# R7FA6M1AD register map
Vendor: Renesas; Series: RA6; File version: 1.2
CPU: CM4 r0p1, little endian, MPU, FPU, VTOR, 4 interrupt priority bits
Registers are 8-bit, read-write, reset 0x0 unless marked. A register's access mark holds for its fields unless they carry their own. Offsets are from the block's base; [hi:lo] are bit positions.

## CTSU — Capacitive Touch Sensing Unit
Base 0x40081000
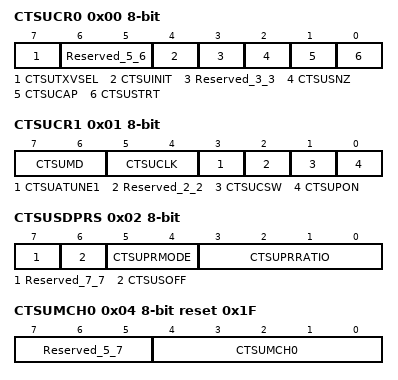
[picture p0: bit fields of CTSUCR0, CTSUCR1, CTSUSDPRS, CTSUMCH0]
0x00 CTSUCR0 — CTSU Control Register 0
  [7] CTSUTXVSEL — CTSU Transmission power supply selection
  [6:5] Reserved_5_6 — These bits are read as 00. The write value should be 00.
  [4] CTSUINIT — CTSU Control Block Initialization
  [3] Reserved_3_3 — This bit is read as 0. The write value should be 0.
  [2] CTSUSNZ — CTSU Wait State Power,Saving Enable
  [1] CTSUCAP — CTSU Measurement Operation Start Trigger Select
  [0] CTSUSTRT — CTSU Measurement Operation Start
0x01 CTSUCR1 — CTSU Control Register 1
  [7:6] CTSUMD — CTSU Measurement Mode Select
  [5:4] CTSUCLK — CTSU Operating Clock Select
  [3] CTSUATUNE1 — CTSU Power Supply Capacity Adjustment
  [2] Reserved_2_2 — This bit is read as 0. The write value should be 0.
  [1] CTSUCSW — CTSU LPF Capacitance Charging Control
  [0] CTSUPON — CTSU Power Supply Enable
0x02 CTSUSDPRS — CTSU Synchronous Noise Reduction Setting Register
  [7] Reserved_7_7 — This bit is read as 0. The write value should be 0.
  [6] CTSUSOFF — CTSU High,Pass Noise Reduction Function Off Setting
  [5:4] CTSUPRMODE — CTSU Base Period and Pulse Count Setting
  [3:0] CTSUPRRATIO — CTSU Measurement Time and Pulse Count Adjustment Recommended setting: 3 (0011b)
0x03 CTSUSST — CTSU Sensor Stabilization Wait Control Register
  [7:0] CTSUSST — CTSU Sensor Stabilization Wait Control NOTE: The value of these bits should be fixed to 00010000b.
0x04 CTSUMCH0 reset 0x1F — CTSU Measurement Channel Register 0
  [7:5] Reserved_5_7 — These bits are read as 000. The write value should be 000.
  [4:0] CTSUMCH0 — CTSU Measurement Channel 0. Note1: Writing to these bits is only enabled in self,capacitance single scan mode (CTSUCR1.CTSUMD[1:0] bits = 00b). Note2: If the value of CTSUMCH0 was set to b'11111 in mode other than self,capacitor single scan mode, the measurement is stopped.
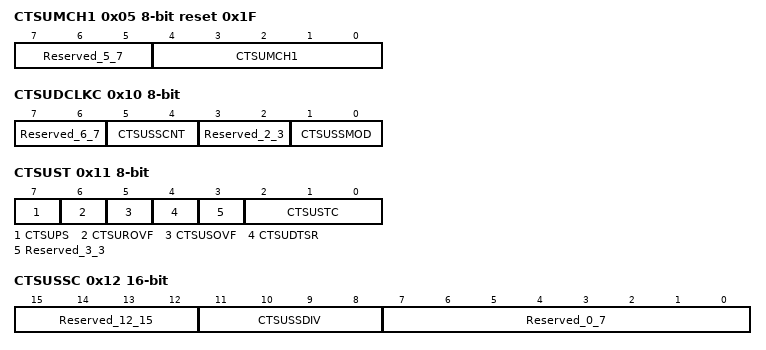
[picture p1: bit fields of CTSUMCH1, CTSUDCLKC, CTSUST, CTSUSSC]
0x05 CTSUMCH1 ro reset 0x1F — CTSU Measurement Channel Register 1
  [7:5] Reserved_5_7 — These bits are read as 000.
  [4:0] CTSUMCH1 — CTSU Measurement Channel 1 Note1: If the value of CTSUMCH1 was set to b'11111, the measurement is stopped.
0x06 CTSUCHAC0 — CTSU Channel Enable Control Register 0
  [7] CTSUCHAC0 — CTSU Channel Enable Control 0. 0: Not measurement target 1: Measurement target Note: Bit 1 corresponds to TS01 and Bit 7 corresponds to TS07.
0x07 CTSUCHAC1 — CTSU Channel Enable Control Register 1
  [4:0] CTSUCHAC1 — CTSU Channel Enable Control 1. 0: Not measurement target 1: Measurement target Note: CTSUCHAC1[0] corresponds to TS08 and CTSUCHAC1[4] corresponds to TS12.
0x0B CTSUCHTRC0 — CTSU Channel Transmit/Receive Control Register 0
  [0] Reserved_0_0 — This bit is read as 0. The write value should be 0.
0x0C CTSUCHTRC1 — CTSU Channel Transmit/Receive Control Register 1
  [7:5] Reserved_5_7 — These bits are read as 000. The write value should be 000.
0x10 CTSUDCLKC — CTSU High,Pass Noise Reduction Control Register
  [7:6] Reserved_6_7 — These bits are read as 00. The write value should be 00.
  [5:4] CTSUSSCNT — CTSU Diffusion Clock Mode Control NOTE: This bit should be set to 11b.
  [3:2] Reserved_2_3 — These bits are read as 00. The write value should be 00.
  [1:0] CTSUSSMOD — CTSU Diffusion Clock Mode Select NOTE: This bit should be set to 00b.
0x11 CTSUST — CTSU Status Register
  [7] CTSUPS ro — CTSU Mutual Capacitance Status Flag
  [6] CTSUROVF — CTSU Reference Counter Overflow Flag
  [5] CTSUSOVF — CTSU Sensor Counter Overflow Flag
  [4] CTSUDTSR ro — CTSU Data Transfer Status Flag
  [3] Reserved_3_3 — This bit is read as 0. The write value should be 0.
  [2:0] CTSUSTC ro — CTSU Measurement Status Counter
0x12 CTSUSSC 16-bit — CTSU High,Pass Noise Reduction Spectrum Diffusion Control Register
  [15:12] Reserved_12_15 — These bits are read as 0000. The write value should be 0000.
  [11:8] CTSUSSDIV — CTSU Spectrum Diffusion Frequency Division Setting
  [7:0] Reserved_0_7 — These bits are read as 00000000. The write value should be 00000000.
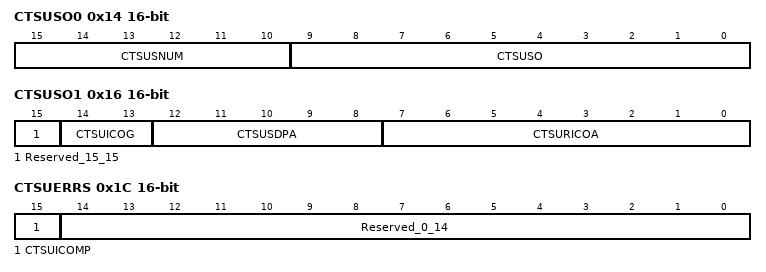
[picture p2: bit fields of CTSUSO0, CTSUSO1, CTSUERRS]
0x14 CTSUSO0 16-bit — CTSU Sensor Offset Register 0
  [15:10] CTSUSNUM — CTSU Measurement Count Setting
  [9:0] CTSUSO — CTSU Sensor Offset Adjustment Current offset amount is CTSUSO ( 0 to 1023 )
0x16 CTSUSO1 16-bit — CTSU Sensor Offset Register 1
  [15] Reserved_15_15 — This bit is read as 0. The write value should be 0.
  [14:13] CTSUICOG — CTSU ICO Gain Adjustment
  [12:8] CTSUSDPA — CTSU Base Clock Setting Operating clock divided by ( CTSUSDPA + 1 ) x 2
  [7:0] CTSURICOA — CTSU Reference ICO Current Adjustment Current offset amount is CTSUSO ( 0 to 255 )
0x18 CTSUSC 16-bit ro — CTSU Sensor Counter
  [15:0] CTSUSC — CTSU Sensor Counter These bits indicate the measurement result of the CTSU. These bits indicate FFFFh when an overflow occurs.
0x1A CTSURC 16-bit ro — CTSU Reference Counter
0x1C CTSUERRS 16-bit ro (reset mask 0x7FFF) — CTSU Error Status Register
  [15] CTSUICOMP — TSCAP Voltage Error Monitor
  [14:0] Reserved_0_14 — These bits are read as 000000000000000.
